# EFR32BG21A020F1024IM32 register map
Vendor: Silicon Labs; Series: EFR32; File version: B
Registers are 32-bit, read-write, reset 0x0 unless marked. A register's access mark holds for its fields unless they carry their own. Offsets are from the block's base; [hi:lo] are bit positions; {n}, {i} and the like mark numbered series; 'fields as' and 'values as' point back to an identical list.

## PRS_S — PRS_S Registers
Base 0x40038000
Same registers: PRS_NS 0x50038000
0x00 IPVERSION ro
  [31:0] IPVERSION — IP version ID
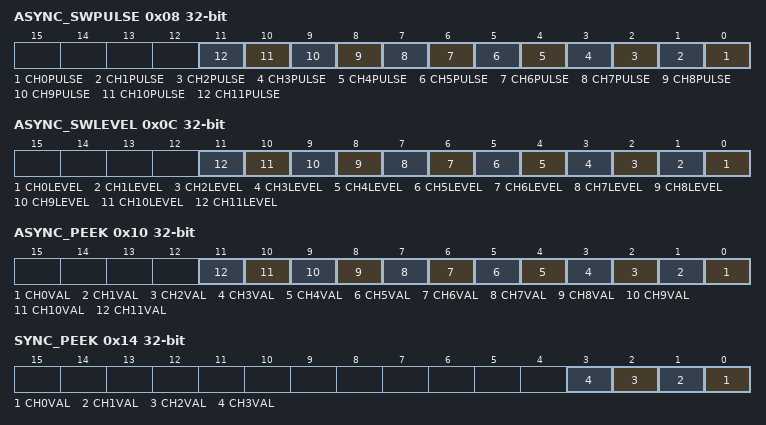
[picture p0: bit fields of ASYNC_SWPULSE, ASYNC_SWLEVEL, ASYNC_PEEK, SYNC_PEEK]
0x08 ASYNC_SWPULSE wo
  [n] CH{n}PULSE (n=0..11) — Channel pulse
0x0C ASYNC_SWLEVEL
  [n] CH{n}LEVEL (n=0..11) — Channel Level
0x10 ASYNC_PEEK ro
  [n] CH{n}VAL (n=0..11) — Channel {n} Current Value
0x14 SYNC_PEEK ro
  [n] CH{n}VAL (n=0..3) — Channel {n} Current Value
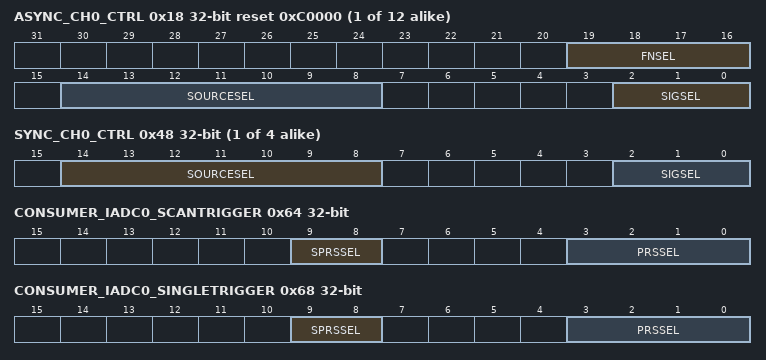
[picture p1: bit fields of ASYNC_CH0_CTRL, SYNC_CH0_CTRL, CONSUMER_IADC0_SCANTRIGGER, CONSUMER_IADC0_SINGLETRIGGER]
{0x18+4i} ASYNC_CH{i}_CTRL reset 0xC0000 (i=0..11)
  [19:16] FNSEL — Function Select
    0=LOGICAL_ZERO (Logical 0); 1=A_NOR_B; 2=NOT_A_AND_B ((!A) AND B); 3=NOT_A (!A); 4=A_AND_NOT_B (A AND (!B)); 5=NOT_B (!B); 6=A_XOR_B; 7=A_NAND_B; 8=A_AND_B; 9=A_XNOR_B; 10=B; 11=NOT_A_OR_B ((!A) OR B); 12=A; 13=A_OR_NOT_B (A OR (!B)); 14=A_OR_B; 15=LOGICAL_ONE (Logical 1)
  [14:8] SOURCESEL — Source Select
  [2:0] SIGSEL — Signal Select
    0=NONE
{0x48+4i} SYNC_CH{i}_CTRL (i=0..3)
  [14:8] SOURCESEL — Source Select
  [2:0] SIGSEL — Signal Select
    0=NONE
0x58 CONSUMER_CMU_CALDN
  [3:0] PRSSEL — Asynchronous Channel Selection
0x5C CONSUMER_CMU_CALUP
  [3:0] PRSSEL — Asynchronous Channel Selection
0x64 CONSUMER_IADC0_SCANTRIGGER
  [9:8] SPRSSEL — Synchronous Channel Selection
  [3:0] PRSSEL — Asynchronous Channel Selection
0x68 CONSUMER_IADC0_SINGLETRIGGER
  fields as CONSUMER_IADC0_SCANTRIGGER
0x6C CONSUMER_LDMAXBAR_DMAREQ0
  [3:0] PRSSEL — Asynchronous Channel Selection
0x70 CONSUMER_LDMAXBAR_DMAREQ1
  [3:0] PRSSEL — Asynchronous Channel Selection
0x74 CONSUMER_LETIMER0_CLEAR
  [3:0] PRSSEL — Asynchronous Channel Selection
0x78 CONSUMER_LETIMER0_START
  [3:0] PRSSEL — Asynchronous Channel Selection
0x7C CONSUMER_LETIMER0_STOP
  [3:0] PRSSEL — Asynchronous Channel Selection
0x80 CONSUMER_MODEM_DIN
  [3:0] PRSSEL — Asynchronous Channel Selection
0xB8 CONSUMER_RAC_CLR
  [3:0] PRSSEL — Asynchronous Channel Selection
0xBC CONSUMER_RAC_FORCETX
  [3:0] PRSSEL — Asynchronous Channel Selection
0xC0 CONSUMER_RAC_RXDIS
  [3:0] PRSSEL — Asynchronous Channel Selection
0xC4 CONSUMER_RAC_RXEN
  [3:0] PRSSEL — Asynchronous Channel Selection
0xC8 CONSUMER_RAC_SEQ
  [3:0] PRSSEL — Asynchronous Channel Selection
0xCC CONSUMER_RAC_TXEN
  [3:0] PRSSEL — Asynchronous Channel Selection
{0xD0+4i} CONSUMER_RTCC_CC{i} (i=0..2)
  [3:0] PRSSEL — Asynchronous Channel Selection
{0xE0+4i} CONSUMER_SE_TAMPERSRC{i} (i=0..7)
  [3:0] PRSSEL — Asynchronous Channel Selection
{0x108+4i} CONSUMER_CORE_CTIIN{i} (i=0..3)
  [3:0] PRSSEL — Asynchronous Channel Selection
0x118 CONSUMER_CORE_M33RXEV
  [3:0] PRSSEL — Asynchronous Channel Selection
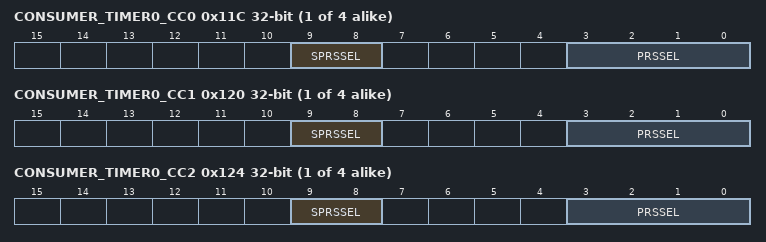
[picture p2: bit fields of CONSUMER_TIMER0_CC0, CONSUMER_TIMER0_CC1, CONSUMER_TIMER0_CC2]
{0x11C+0x18*i} CONSUMER_TIMER{i}_CC0 (i=0..3)
  fields as CONSUMER_IADC0_SCANTRIGGER
{0x120+0x18*i} CONSUMER_TIMER{i}_CC1 (i=0..3)
  fields as CONSUMER_IADC0_SCANTRIGGER
{0x124+0x18*i} CONSUMER_TIMER{i}_CC2 (i=0..3)
  fields as CONSUMER_IADC0_SCANTRIGGER
{0x128+0x18*i} CONSUMER_TIMER{i}_DTI (i=0..3)
  [3:0] PRSSEL — Asynchronous Channel Selection
{0x12C+0x18*i} CONSUMER_TIMER{i}_DTIFS1 (i=0..3)
  [3:0] PRSSEL — Asynchronous Channel Selection
{0x130+0x18*i} CONSUMER_TIMER{i}_DTIFS2 (i=0..3)
  [3:0] PRSSEL — Asynchronous Channel Selection
{0x17C+0x10*i} CONSUMER_USART{i}_CLK (i=0..2)
  [3:0] PRSSEL — Asynchronous Channel Selection
{0x180+0x10*i} CONSUMER_USART{i}_IR (i=0..2)
  [3:0] PRSSEL — Asynchronous Channel Selection
{0x184+0x10*i} CONSUMER_USART{i}_RX (i=0..2)
  [3:0] PRSSEL — Asynchronous Channel Selection
{0x188+0x10*i} CONSUMER_USART{i}_TRIGGER (i=0..2)
  [3:0] PRSSEL — Asynchronous Channel Selection
0x1AC CONSUMER_WDOG0_SRC0
  [3:0] PRSSEL — Asynchronous Channel Selection
0x1B0 CONSUMER_WDOG0_SRC1
  [3:0] PRSSEL — Asynchronous Channel Selection
0x1B4 CONSUMER_WDOG1_SRC0
  [3:0] PRSSEL — Asynchronous Channel Selection
0x1B8 CONSUMER_WDOG1_SRC1
  [3:0] PRSSEL — Asynchronous Channel Selection
